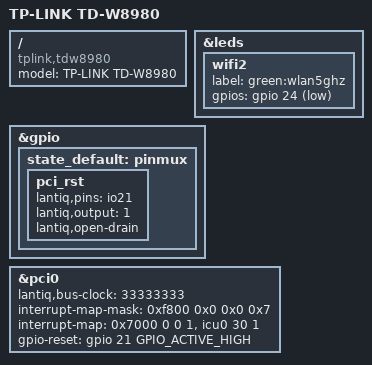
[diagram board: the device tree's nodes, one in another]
#include "vr9_tplink_tdw89x0.dtsi"

/ {
	compatible = "tplink,tdw8980", "tplink,tdw89x0", "lantiq,xway", "lantiq,vr9";
	model = "TP-LINK TD-W8980";
};

&leds {
	wifi2 {
		label = "green:wlan5ghz";
		gpios = <&gpio 24 GPIO_ACTIVE_LOW>;
	};
};

&gpio {
	state_default: pinmux {
		pci_rst {
			lantiq,pins = "io21";
			lantiq,output = <1>;
			lantiq,open-drain;
		};
	};
};

&pci0 {
	status = "okay";
	lantiq,bus-clock = <33333333>;
	interrupt-map-mask = <0xf800 0x0 0x0 0x7>;
	interrupt-map = <0x7000 0 0 1 &icu0 30 1>;
	gpio-reset = <&gpio 21 GPIO_ACTIVE_HIGH>;
};
